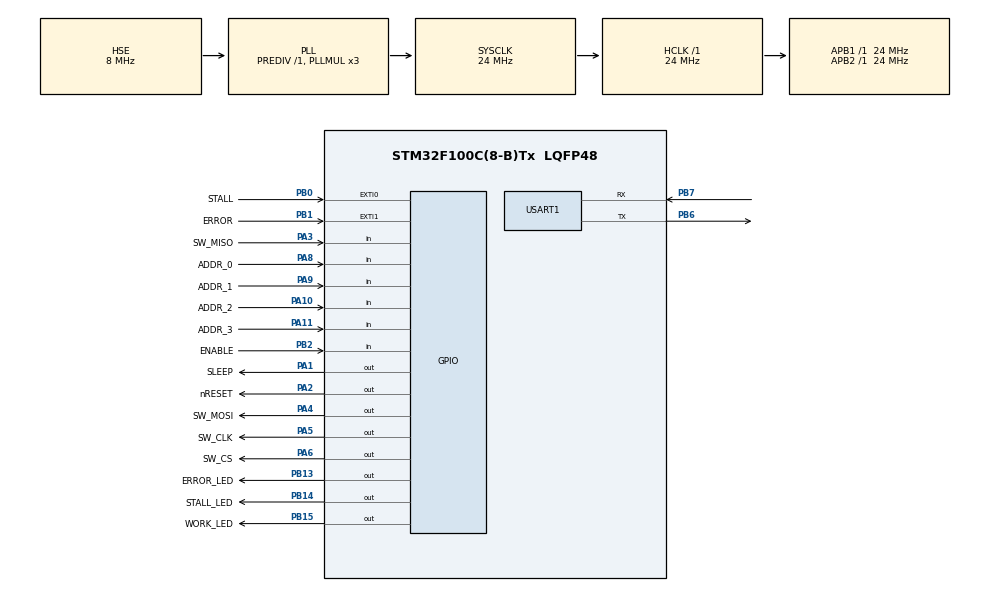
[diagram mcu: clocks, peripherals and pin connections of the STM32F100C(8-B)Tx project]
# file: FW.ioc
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Mcu.Family=STM32F1
Mcu.Name=STM32F100C(8-B)Tx
Mcu.Package=LQFP48
NVIC.PriorityGroup=NVIC_PRIORITYGROUP_4
PA1.GPIO_Label=SLEEP
PA1.Signal=GPIO_Output
PA10.GPIO_Label=ADDR_2
PA10.Signal=GPIO_Input
PA11.GPIO_Label=ADDR_3
PA11.Signal=GPIO_Input
PA13.Mode=Serial_Wire
PA13.Signal=SYS_JTMS-SWDIO
PA14.Mode=Serial_Wire
PA14.Signal=SYS_JTCK-SWCLK
PA2.GPIO_Label=nRESET
PA2.Signal=GPIO_Output
PA3.GPIO_Label=SW_MISO
PA3.Signal=GPIO_Input
PA4.GPIO_Label=SW_MOSI
PA4.GPIO_Speed=GPIO_SPEED_FREQ_HIGH
PA4.Signal=GPIO_Output
PA5.GPIO_Label=SW_CLK
PA5.GPIO_Speed=GPIO_SPEED_FREQ_HIGH
PA5.Signal=GPIO_Output
PA6.GPIO_Label=SW_CS
PA6.Signal=GPIO_Output
PA8.GPIO_Label=ADDR_0
PA8.Signal=GPIO_Input
PA9.GPIO_Label=ADDR_1
PA9.Signal=GPIO_Input
PB0.GPIO_Label=STALL
PB0.Signal=GPXTI0
PB1.GPIO_Label=ERROR
PB1.Signal=GPXTI1
PB13.GPIO_Label=ERROR_LED
PB13.Signal=GPIO_Output
PB14.GPIO_Label=STALL_LED
PB14.Signal=GPIO_Output
PB15.GPIO_Label=WORK_LED
PB15.Signal=GPIO_Output
PB2.GPIO_Label=ENABLE
PB2.Signal=GPIO_Input
PB6.Mode=Asynchronous
PB6.Signal=USART1_TX
PB7.Mode=Asynchronous
PB7.Signal=USART1_RX
PD0-OSC_IN.Mode=HSE-External-Oscillator
PD0-OSC_IN.Signal=RCC_OSC_IN
PD1-OSC_OUT.Mode=HSE-External-Oscillator
PD1-OSC_OUT.Signal=RCC_OSC_OUT
ProjectManager.HeapSize=0x200
ProjectManager.StackSize=0x400
ProjectManager.TargetToolchain=Makefile
RCC.AHBFreq_Value=24000000
RCC.APB1Freq_Value=24000000
RCC.APB1TimFreq_Value=24000000
RCC.APB2Freq_Value=24000000
RCC.APB2TimFreq_Value=24000000
RCC.HCLKFreq_Value=24000000
RCC.PLLMUL=RCC_PLL_MUL3
RCC.PLLSource=RCC_PLLSOURCE_HSE
RCC.SYSCLKFreq_VALUE=24000000
RCC.SYSCLKSource=RCC_SYSCLKSOURCE_PLLCLK
USART1.VirtualMode=VM_ASYNC
board=custom

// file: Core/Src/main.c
/* USER CODE BEGIN Header */
/**
  ******************************************************************************
  * @file           : main.c
  * @brief          : Main program body
  ******************************************************************************
  * @attention
  *
  * <h2><center>&copy; Copyright (c) 2020 STMicroelectronics.
  * All rights reserved.</center></h2>
  *
  * This software component is licensed by ST under BSD 3-Clause license,
  * the "License"; You may not use this file except in compliance with the
  * License. You may obtain a copy of the License at:
  *                        opensource.org/licenses/BSD-3-Clause
  *
  ******************************************************************************
  */
/* USER CODE END Header */
#include "main.h"
#include "usart.h"
#include "gpio.h"

/* USER CODE BEGIN Includes */
#include "drv8711.h"
/* USER CODE END Includes */

void SystemClock_Config(void);

int main(void)
{

  /* MCU Configuration--------------------------------------------------------*/

  /* Reset of all peripherals, Initializes the Flash interface and the Systick. */
  HAL_Init();

  /* Configure the system clock */
  SystemClock_Config();

  /* Initialize all configured peripherals */
  MX_GPIO_Init();
  MX_USART1_UART_Init();
  /* USER CODE BEGIN 2 */
  HAL_GPIO_WritePin(WORK_LED_GPIO_Port,WORK_LED_Pin,GPIO_PIN_SET);
  HAL_UART_Transmit(&huart1,(uint8_t*)"Start\n\r",7,10);
  /* USER CODE END 2 */

  /* Infinite loop */
  while (1)
  {

  }
}

void SystemClock_Config(void)
{
  RCC_OscInitTypeDef RCC_OscInitStruct = {0};
  RCC_ClkInitTypeDef RCC_ClkInitStruct = {0};

  /** Initializes the RCC Oscillators according to the specified parameters
  * in the RCC_OscInitTypeDef structure.
  */
  RCC_OscInitStruct.OscillatorType = RCC_OSCILLATORTYPE_HSE;
  RCC_OscInitStruct.HSEState = RCC_HSE_ON;
  RCC_OscInitStruct.HSEPredivValue = RCC_HSE_PREDIV_DIV1;
  RCC_OscInitStruct.PLL.PLLState = RCC_PLL_ON;
  RCC_OscInitStruct.PLL.PLLSource = RCC_PLLSOURCE_HSE;
  RCC_OscInitStruct.PLL.PLLMUL = RCC_PLL_MUL3;
  if (HAL_RCC_OscConfig(&RCC_OscInitStruct) != HAL_OK)
  {
    Error_Handler();
  }
  /** Initializes the CPU, AHB and APB buses clocks
  */
  RCC_ClkInitStruct.ClockType = RCC_CLOCKTYPE_HCLK|RCC_CLOCKTYPE_SYSCLK
                              |RCC_CLOCKTYPE_PCLK1|RCC_CLOCKTYPE_PCLK2;
  RCC_ClkInitStruct.SYSCLKSource = RCC_SYSCLKSOURCE_PLLCLK;
  RCC_ClkInitStruct.AHBCLKDivider = RCC_SYSCLK_DIV1;
  RCC_ClkInitStruct.APB1CLKDivider = RCC_HCLK_DIV1;
  RCC_ClkInitStruct.APB2CLKDivider = RCC_HCLK_DIV1;

  if (HAL_RCC_ClockConfig(&RCC_ClkInitStruct, FLASH_LATENCY_0) != HAL_OK)
  {
    Error_Handler();
  }
}

void Error_Handler(void)
{
}

/************************ (C) COPYRIGHT STMicroelectronics *****END OF FILE****/
